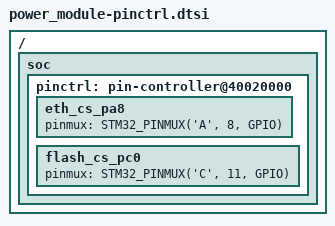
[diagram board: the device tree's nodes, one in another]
/ {
	soc {
		pinctrl: pin-controller@40020000 {
            eth_cs_pa8: eth_cs_pa8 {
                pinmux = <STM32_PINMUX('A', 8, GPIO)>;
            };

            flash_cs_pc0: flash_cs_pc0 {
                pinmux = <STM32_PINMUX('C', 11, GPIO)>;
            };
        };
    };
};
